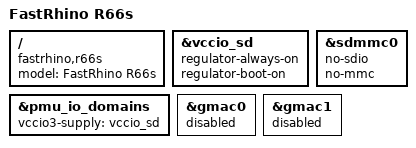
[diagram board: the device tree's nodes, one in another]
// SPDX-License-Identifier: (GPL-2.0+ OR MIT)
/*
 * Copyright (c) 2020 Rockchip Electronics Co., Ltd.
 *
 */

/dts-v1/;

#include "rk3568-fastrhino-core.dtsi"

/ {
	model = "FastRhino R66s";
	compatible = "fastrhino,r66s", "rockchip,rk3568";

};

/ {
	/delete-node/ adc-keys;
};

&vccio_sd {
	regulator-always-on;
	regulator-boot-on;
};

&pmu_io_domains {
	vccio3-supply = <&vccio_sd>;
};

&sdmmc0 {
	no-sdio;
	no-mmc;
	/delete-property/ sd-uhs-sdr104;
	status = "okay";
};

&gmac0 {
	status = "disabled";
};

&gmac1 {
	status = "disabled";
};
